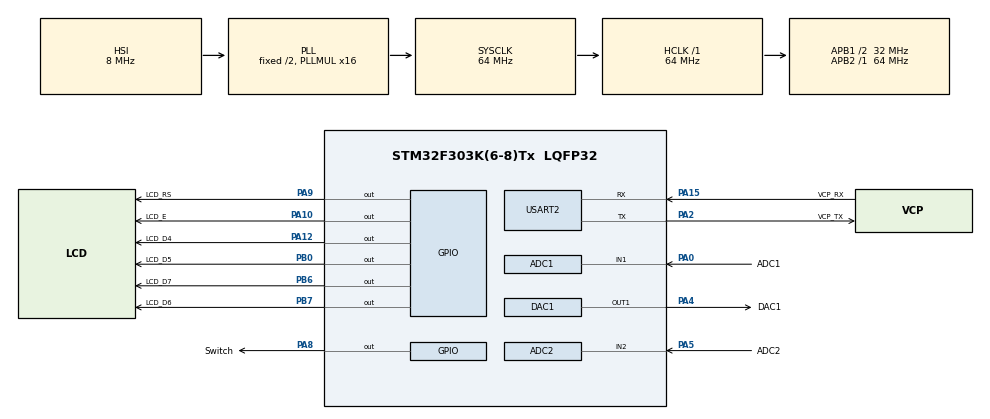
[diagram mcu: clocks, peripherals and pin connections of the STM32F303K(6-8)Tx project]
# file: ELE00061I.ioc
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ADC1.Channel-0\#ChannelRegularConversion=ADC_CHANNEL_1
ADC1.ClockPrescaler=ADC_CLOCK_SYNC_PCLK_DIV4
ADC1.DMAContinuousRequests=ENABLE
ADC1.ExternalTrigConv=ADC_EXTERNALTRIGCONV_T6_TRGO
ADC1.Mode=ADC_DUALMODE_REGSIMULT
ADC1.NbrOfConversion=1
ADC1.NbrOfConversionFlag=1
ADC1.Offset-0\#ChannelRegularConversion=0
ADC1.OffsetNumber-0\#ChannelRegularConversion=ADC_OFFSET_NONE
ADC1.Rank-0\#ChannelRegularConversion=1
ADC1.SamplingTime-0\#ChannelRegularConversion=ADC_SAMPLETIME_61CYCLES_5
ADC1.SamplingTimeOPAMP-0\#ChannelRegularConversion=ADC_SAMPLETIME_61CYCLES_5
ADC1.SubFamily=STM32F303x8
ADC1.master=1
ADC2.Channel-0\#ChannelRegularConversion=ADC_CHANNEL_2
ADC2.ClockPrescaler=ADC_CLOCK_SYNC_PCLK_DIV4
ADC2.DMAContinuousRequests=ENABLE
ADC2.Mode=ADC_DUALMODE_REGSIMULT
ADC2.NbrOfConversionFlag=1
ADC2.Offset-0\#ChannelRegularConversion=0
ADC2.OffsetNumber-0\#ChannelRegularConversion=ADC_OFFSET_NONE
ADC2.Rank-0\#ChannelRegularConversion=1
ADC2.SamplingTime-0\#ChannelRegularConversion=ADC_SAMPLETIME_61CYCLES_5
ADC2.SamplingTimeOPAMP-0\#ChannelRegularConversion=ADC_SAMPLETIME_61CYCLES_5
ADC2.SubFamily=STM32F303x8
DAC1.DAC_OutputBuffer=DAC_OUTPUTBUFFER_ENABLE
DAC1.DAC_Trigger=DAC_TRIGGER_T6_TRGO
Dma.ADC1.2.Direction=DMA_PERIPH_TO_MEMORY
Dma.ADC1.2.Instance=DMA1_Channel1
Dma.ADC1.2.MemDataAlignment=DMA_MDATAALIGN_WORD
Dma.ADC1.2.MemInc=DMA_MINC_ENABLE
Dma.ADC1.2.Mode=DMA_CIRCULAR
Dma.ADC1.2.PeriphDataAlignment=DMA_PDATAALIGN_WORD
Dma.ADC1.2.PeriphInc=DMA_PINC_DISABLE
Dma.ADC1.2.Priority=DMA_PRIORITY_LOW
Dma.ADC2.1.Direction=DMA_PERIPH_TO_MEMORY
Dma.ADC2.1.Instance=DMA1_Channel2
Dma.ADC2.1.MemDataAlignment=DMA_MDATAALIGN_HALFWORD
Dma.ADC2.1.MemInc=DMA_MINC_ENABLE
Dma.ADC2.1.Mode=DMA_CIRCULAR
Dma.ADC2.1.PeriphDataAlignment=DMA_PDATAALIGN_HALFWORD
Dma.ADC2.1.PeriphInc=DMA_PINC_DISABLE
Dma.ADC2.1.Priority=DMA_PRIORITY_LOW
Dma.DAC1_CH1.0.Direction=DMA_MEMORY_TO_PERIPH
Dma.DAC1_CH1.0.Instance=DMA1_Channel3
Dma.DAC1_CH1.0.MemDataAlignment=DMA_MDATAALIGN_HALFWORD
Dma.DAC1_CH1.0.MemInc=DMA_MINC_ENABLE
Dma.DAC1_CH1.0.Mode=DMA_CIRCULAR
Dma.DAC1_CH1.0.PeriphDataAlignment=DMA_PDATAALIGN_HALFWORD
Dma.DAC1_CH1.0.PeriphInc=DMA_PINC_DISABLE
Dma.DAC1_CH1.0.Priority=DMA_PRIORITY_LOW
Dma.Request0=DAC1_CH1
Dma.Request1=ADC2
Dma.Request2=ADC1
Mcu.Family=STM32F3
Mcu.Name=STM32F303K(6-8)Tx
Mcu.Package=LQFP32
NVIC.DMA1_Channel1_IRQn=true\:0\:0\:false\:false\:true\:false\:true\:true
NVIC.DMA1_Channel2_IRQn=true\:0\:0\:false\:false\:true\:false\:true\:true
NVIC.DMA1_Channel3_IRQn=true\:0\:0\:false\:false\:true\:false\:true\:true
NVIC.PriorityGroup=NVIC_PRIORITYGROUP_4
PA0.GPIO_Label=ADC1
PA0.Mode=IN1-Single-Ended
PA0.Signal=ADC1_IN1
PA10.GPIO_Label=LCD_E
PA10.Signal=GPIO_Output
PA12.GPIO_Label=LCD_D4
PA12.Signal=GPIO_Output
PA13.GPIO_Label=SWDIO
PA13.Mode=Serial_Wire
PA13.Signal=SYS_JTMS-SWDIO
PA14.GPIO_Label=SWCLK
PA14.Mode=Serial_Wire
PA14.Signal=SYS_JTCK-SWCLK
PA15.GPIO_Label=VCP_RX
PA15.Mode=Asynchronous
PA15.Signal=USART2_RX
PA2.GPIO_Label=VCP_TX
PA2.Mode=Asynchronous
PA2.Signal=USART2_TX
PA4.GPIO_Label=DAC1
PA4.GPIO_Mode=GPIO_MODE_ANALOG
PA4.Signal=COMP_DAC11_group
PA5.GPIO_Label=ADC2
PA5.Mode=IN2-Single-Ended
PA5.Signal=ADC2_IN2
PA8.GPIO_Label=Switch
PA8.Signal=GPIO_Output
PA9.GPIO_Label=LCD_RS
PA9.Signal=GPIO_Output
PB0.GPIO_Label=LCD_D5
PB0.Signal=GPIO_Output
PB6.GPIO_Label=LCD_D7
PB6.Signal=GPIO_Output
PB7.GPIO_Label=LCD_D6
PB7.Signal=GPIO_Output
PF0\ /\ OSC_IN.GPIO_Label=MCO
PF0\ /\ OSC_IN.Mode=HSE-External-Clock-Source
PF0\ /\ OSC_IN.Signal=RCC_OSC_IN
ProjectManager.HeapSize=0x200
ProjectManager.StackSize=0x400
ProjectManager.TargetToolchain=STM32CubeIDE
RCC.AHBFreq_Value=64000000
RCC.APB1CLKDivider=RCC_HCLK_DIV2
RCC.APB1Freq_Value=32000000
RCC.APB1TimFreq_Value=64000000
RCC.APB2Freq_Value=64000000
RCC.APB2TimFreq_Value=64000000
RCC.CortexFreq_Value=64000000
RCC.HCLKFreq_Value=64000000
RCC.HSE_VALUE=8000000
RCC.HSI_VALUE=8000000
RCC.PLLMUL=RCC_PLL_MUL16
RCC.SYSCLKFreq_VALUE=64000000
RCC.SYSCLKSourceVirtual=RCC_SYSCLKSOURCE_PLLCLK
SH.COMP_DAC11_group.0=DAC1_OUT1,DAC_OUT1
TIM6.Period=10-1
TIM6.Prescaler=1000-1
TIM6.TIM_MasterOutputTrigger=TIM_TRGO_UPDATE
USART2.VirtualMode-Asynchronous=VM_ASYNC
VP_TIM6_VS_ClockSourceINT.Mode=Enable_Timer
board=NUCLEO-F303K8

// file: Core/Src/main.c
/* USER CODE BEGIN Header */
/**
  ******************************************************************************
  * @file           : main.c
  * @brief          : Main program body
  ******************************************************************************
  * @attention
  *
  * Copyright (c) 2025 STMicroelectronics.
  * All rights reserved.
  *
  * This software is licensed under terms that can be found in the LICENSE file
  * in the root directory of this software component.
  * If no LICENSE file comes with this software, it is provided AS-IS.
  *
  ******************************************************************************
  */
/* USER CODE END Header */
#include "main.h"

/* USER CODE BEGIN Includes */
#include "tinkertech.h"
/* USER CODE END Includes */

ADC_HandleTypeDef hadc1;
ADC_HandleTypeDef hadc2;
DMA_HandleTypeDef hdma_adc1;
DMA_HandleTypeDef hdma_adc2;

DAC_HandleTypeDef hdac1;
DMA_HandleTypeDef hdma_dac1_ch1;

TIM_HandleTypeDef htim6;

UART_HandleTypeDef huart2;

void SystemClock_Config(void);
static void MX_GPIO_Init(void);
static void MX_DMA_Init(void);
static void MX_USART2_UART_Init(void);
static void MX_ADC1_Init(void);
static void MX_ADC2_Init(void);
static void MX_DAC1_Init(void);
static void MX_TIM6_Init(void);

int main(void)
{

  /* MCU Configuration--------------------------------------------------------*/

  /* Reset of all peripherals, Initializes the Flash interface and the Systick. */
  HAL_Init();

  /* Configure the system clock */
  SystemClock_Config();

  /* Initialize all configured peripherals */
  MX_GPIO_Init();
  MX_DMA_Init();
  MX_USART2_UART_Init();
  MX_ADC1_Init();
  MX_ADC2_Init();
  MX_DAC1_Init();
  MX_TIM6_Init();
  /* USER CODE BEGIN 2 */
  setup();
  /* USER CODE END 2 */

  /* Infinite loop */
  while (1)
  {

    /* USER CODE BEGIN 3 */
    loop();
  }
  /* USER CODE END 3 */
}

void SystemClock_Config(void)
{
  RCC_OscInitTypeDef RCC_OscInitStruct = {0};
  RCC_ClkInitTypeDef RCC_ClkInitStruct = {0};

  /** Initializes the RCC Oscillators according to the specified parameters
  * in the RCC_OscInitTypeDef structure.
  */
  RCC_OscInitStruct.OscillatorType = RCC_OSCILLATORTYPE_HSI;
  RCC_OscInitStruct.HSIState = RCC_HSI_ON;
  RCC_OscInitStruct.HSICalibrationValue = RCC_HSICALIBRATION_DEFAULT;
  RCC_OscInitStruct.PLL.PLLState = RCC_PLL_ON;
  RCC_OscInitStruct.PLL.PLLSource = RCC_PLLSOURCE_HSI;
  RCC_OscInitStruct.PLL.PLLMUL = RCC_PLL_MUL16;
  if (HAL_RCC_OscConfig(&RCC_OscInitStruct) != HAL_OK)
  {
    Error_Handler();
  }

  /** Initializes the CPU, AHB and APB buses clocks
  */
  RCC_ClkInitStruct.ClockType = RCC_CLOCKTYPE_HCLK|RCC_CLOCKTYPE_SYSCLK
                              |RCC_CLOCKTYPE_PCLK1|RCC_CLOCKTYPE_PCLK2;
  RCC_ClkInitStruct.SYSCLKSource = RCC_SYSCLKSOURCE_PLLCLK;
  RCC_ClkInitStruct.AHBCLKDivider = RCC_SYSCLK_DIV1;
  RCC_ClkInitStruct.APB1CLKDivider = RCC_HCLK_DIV2;
  RCC_ClkInitStruct.APB2CLKDivider = RCC_HCLK_DIV1;

  if (HAL_RCC_ClockConfig(&RCC_ClkInitStruct, FLASH_LATENCY_2) != HAL_OK)
  {
    Error_Handler();
  }
}

static void MX_ADC1_Init(void)
{

  ADC_MultiModeTypeDef multimode = {0};
  ADC_ChannelConfTypeDef sConfig = {0};

  /** Common config
  */
  hadc1.Instance = ADC1;
  hadc1.Init.ClockPrescaler = ADC_CLOCK_SYNC_PCLK_DIV4;
  hadc1.Init.Resolution = ADC_RESOLUTION_12B;
  hadc1.Init.ScanConvMode = ADC_SCAN_DISABLE;
  hadc1.Init.ContinuousConvMode = DISABLE;
  hadc1.Init.DiscontinuousConvMode = DISABLE;
  hadc1.Init.ExternalTrigConvEdge = ADC_EXTERNALTRIGCONVEDGE_RISING;
  hadc1.Init.ExternalTrigConv = ADC_EXTERNALTRIGCONV_T6_TRGO;
  hadc1.Init.DataAlign = ADC_DATAALIGN_RIGHT;
  hadc1.Init.NbrOfConversion = 1;
  hadc1.Init.DMAContinuousRequests = ENABLE;
  hadc1.Init.EOCSelection = ADC_EOC_SINGLE_CONV;
  hadc1.Init.LowPowerAutoWait = DISABLE;
  hadc1.Init.Overrun = ADC_OVR_DATA_OVERWRITTEN;
  if (HAL_ADC_Init(&hadc1) != HAL_OK)
  {
    Error_Handler();
  }

  /** Configure the ADC multi-mode
  */
  multimode.Mode = ADC_DUALMODE_REGSIMULT;
  multimode.DMAAccessMode = ADC_DMAACCESSMODE_12_10_BITS;
  multimode.TwoSamplingDelay = ADC_TWOSAMPLINGDELAY_1CYCLE;
  if (HAL_ADCEx_MultiModeConfigChannel(&hadc1, &multimode) != HAL_OK)
  {
    Error_Handler();
  }

  /** Configure Regular Channel
  */
  sConfig.Channel = ADC_CHANNEL_1;
  sConfig.Rank = ADC_REGULAR_RANK_1;
  sConfig.SingleDiff = ADC_SINGLE_ENDED;
  sConfig.SamplingTime = ADC_SAMPLETIME_61CYCLES_5;
  sConfig.OffsetNumber = ADC_OFFSET_NONE;
  sConfig.Offset = 0;
  if (HAL_ADC_ConfigChannel(&hadc1, &sConfig) != HAL_OK)
  {
    Error_Handler();
  }

}

static void MX_ADC2_Init(void)
{

  /* USER CODE BEGIN ADC2_Init 0 */
	GPIO_InitTypeDef GPIO_InitStruct = {0};
	  __HAL_RCC_GPIOA_CLK_ENABLE();
	  GPIO_InitStruct.Pin = GPIO_PIN_5; // PA5 (A4)
	  GPIO_InitStruct.Mode = GPIO_MODE_ANALOG;
	  GPIO_InitStruct.Pull = GPIO_NOPULL;
	  HAL_GPIO_Init(GPIOA, &GPIO_InitStruct);
  /* USER CODE END ADC2_Init 0 */

  ADC_ChannelConfTypeDef sConfig = {0};

  /** Common config
  */
  hadc2.Instance = ADC2;
  hadc2.Init.ClockPrescaler = ADC_CLOCK_SYNC_PCLK_DIV4;
  hadc2.Init.Resolution = ADC_RESOLUTION_12B;
  hadc2.Init.ScanConvMode = ADC_SCAN_DISABLE;
  hadc2.Init.ContinuousConvMode = DISABLE;
  hadc2.Init.DiscontinuousConvMode = DISABLE;
  hadc2.Init.DataAlign = ADC_DATAALIGN_RIGHT;
  hadc2.Init.NbrOfConversion = 1;
  hadc2.Init.DMAContinuousRequests = DISABLE;
  hadc2.Init.EOCSelection = ADC_EOC_SINGLE_CONV;
  hadc2.Init.LowPowerAutoWait = DISABLE;
  hadc2.Init.Overrun = ADC_OVR_DATA_OVERWRITTEN;
  if (HAL_ADC_Init(&hadc2) != HAL_OK)
  {
    Error_Handler();
  }

  /** Configure Regular Channel
  */
  sConfig.Channel = ADC_CHANNEL_2;
  sConfig.Rank = ADC_REGULAR_RANK_1;
  sConfig.SingleDiff = ADC_SINGLE_ENDED;
  sConfig.SamplingTime = ADC_SAMPLETIME_61CYCLES_5;
  sConfig.OffsetNumber = ADC_OFFSET_NONE;
  sConfig.Offset = 0;
  if (HAL_ADC_ConfigChannel(&hadc2, &sConfig) != HAL_OK)
  {
    Error_Handler();
  }

}

static void MX_DAC1_Init(void)
{

  DAC_ChannelConfTypeDef sConfig = {0};

  /** DAC Initialization
  */
  hdac1.Instance = DAC1;
  if (HAL_DAC_Init(&hdac1) != HAL_OK)
  {
    Error_Handler();
  }

  /** DAC channel OUT1 config
  */
  sConfig.DAC_Trigger = DAC_TRIGGER_T6_TRGO;
  sConfig.DAC_OutputBuffer = DAC_OUTPUTBUFFER_ENABLE;
  if (HAL_DAC_ConfigChannel(&hdac1, &sConfig, DAC_CHANNEL_1) != HAL_OK)
  {
    Error_Handler();
  }

}

static void MX_TIM6_Init(void)
{

  TIM_MasterConfigTypeDef sMasterConfig = {0};

  htim6.Instance = TIM6;
  htim6.Init.Prescaler = 10-1;
  htim6.Init.CounterMode = TIM_COUNTERMODE_UP;
  htim6.Init.Period = 10-1;
  htim6.Init.AutoReloadPreload = TIM_AUTORELOAD_PRELOAD_DISABLE;
  if (HAL_TIM_Base_Init(&htim6) != HAL_OK)
  {
    Error_Handler();
  }
  sMasterConfig.MasterOutputTrigger = TIM_TRGO_UPDATE;
  sMasterConfig.MasterSlaveMode = TIM_MASTERSLAVEMODE_DISABLE;
  if (HAL_TIMEx_MasterConfigSynchronization(&htim6, &sMasterConfig) != HAL_OK)
  {
    Error_Handler();
  }

}

static void MX_USART2_UART_Init(void)
{

  huart2.Instance = USART2;
  huart2.Init.BaudRate = 38400;
  huart2.Init.WordLength = UART_WORDLENGTH_8B;
  huart2.Init.StopBits = UART_STOPBITS_1;
  huart2.Init.Parity = UART_PARITY_NONE;
  huart2.Init.Mode = UART_MODE_TX_RX;
  huart2.Init.HwFlowCtl = UART_HWCONTROL_NONE;
  huart2.Init.OverSampling = UART_OVERSAMPLING_16;
  huart2.Init.OneBitSampling = UART_ONE_BIT_SAMPLE_DISABLE;
  huart2.AdvancedInit.AdvFeatureInit = UART_ADVFEATURE_NO_INIT;
  if (HAL_UART_Init(&huart2) != HAL_OK)
  {
    Error_Handler();
  }

}

static void MX_DMA_Init(void)
{

  /* DMA controller clock enable */
  __HAL_RCC_DMA1_CLK_ENABLE();

  /* DMA interrupt init */
  /* DMA1_Channel1_IRQn interrupt configuration */
  HAL_NVIC_SetPriority(DMA1_Channel1_IRQn, 0, 0);
  HAL_NVIC_EnableIRQ(DMA1_Channel1_IRQn);
  /* DMA1_Channel2_IRQn interrupt configuration */
  HAL_NVIC_SetPriority(DMA1_Channel2_IRQn, 0, 0);
  HAL_NVIC_EnableIRQ(DMA1_Channel2_IRQn);
  /* DMA1_Channel3_IRQn interrupt configuration */
  HAL_NVIC_SetPriority(DMA1_Channel3_IRQn, 0, 0);
  HAL_NVIC_EnableIRQ(DMA1_Channel3_IRQn);

}

static void MX_GPIO_Init(void)
{
  GPIO_InitTypeDef GPIO_InitStruct = {0};

  /* GPIO Ports Clock Enable */
  __HAL_RCC_GPIOF_CLK_ENABLE();
  __HAL_RCC_GPIOA_CLK_ENABLE();
  __HAL_RCC_GPIOB_CLK_ENABLE();

  /*Configure GPIO pin Output Level */
  HAL_GPIO_WritePin(GPIOB, LCD_D5_Pin|LCD_D7_Pin|LCD_D6_Pin, GPIO_PIN_RESET);

  /*Configure GPIO pin Output Level */
  HAL_GPIO_WritePin(GPIOA, Switch_Pin|LCD_RS_Pin|LCD_E_Pin|LCD_D4_Pin, GPIO_PIN_RESET);

  /*Configure GPIO pins : LCD_D5_Pin LCD_D7_Pin LCD_D6_Pin */
  GPIO_InitStruct.Pin = LCD_D5_Pin|LCD_D7_Pin|LCD_D6_Pin;
  GPIO_InitStruct.Mode = GPIO_MODE_OUTPUT_PP;
  GPIO_InitStruct.Pull = GPIO_NOPULL;
  GPIO_InitStruct.Speed = GPIO_SPEED_FREQ_LOW;
  HAL_GPIO_Init(GPIOB, &GPIO_InitStruct);

  /*Configure GPIO pins : Switch_Pin LCD_RS_Pin LCD_E_Pin LCD_D4_Pin */
  GPIO_InitStruct.Pin = Switch_Pin|LCD_RS_Pin|LCD_E_Pin|LCD_D4_Pin;
  GPIO_InitStruct.Mode = GPIO_MODE_OUTPUT_PP;
  GPIO_InitStruct.Pull = GPIO_NOPULL;
  GPIO_InitStruct.Speed = GPIO_SPEED_FREQ_LOW;
  HAL_GPIO_Init(GPIOA, &GPIO_InitStruct);

}

void Error_Handler(void)
{
  __disable_irq();
  while (1)
  {
  }
}
